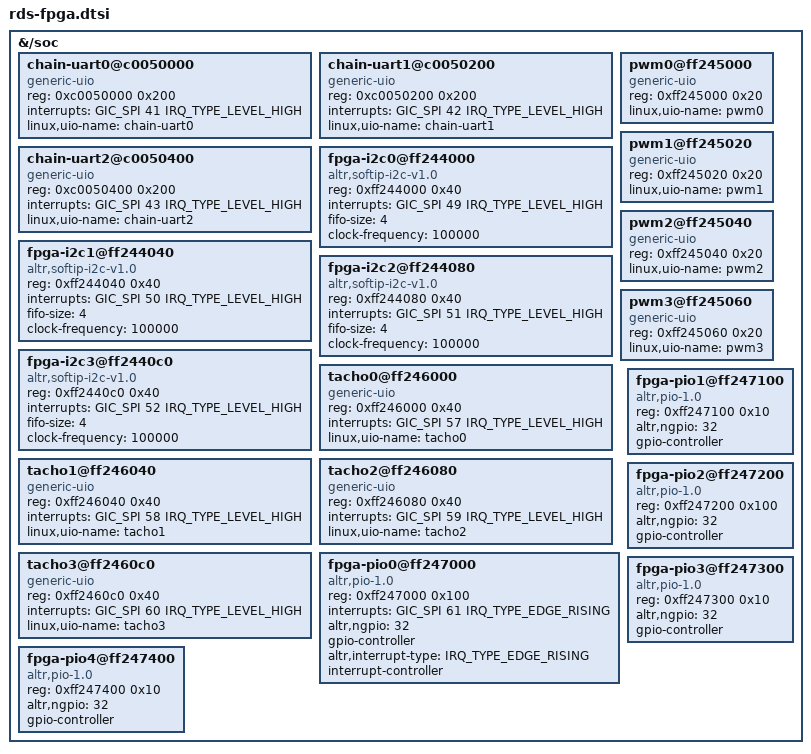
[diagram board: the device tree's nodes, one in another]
// SPDX-License-Identifier: GPL-2.0-or-later
/* GENERATED by tools/hw2dts from os/board/rds-control/hw.toml. Do not edit. */
#include <dt-bindings/interrupt-controller/arm-gic.h>
#include <dt-bindings/interrupt-controller/irq.h>

&{/soc} {
	chain-uart0@c0050000 {
		compatible = "generic-uio";
		reg = <0xc0050000 0x200>;
		interrupts = <GIC_SPI 41 IRQ_TYPE_LEVEL_HIGH>;
		linux,uio-name = "chain-uart0";
	};
	chain-uart1@c0050200 {
		compatible = "generic-uio";
		reg = <0xc0050200 0x200>;
		interrupts = <GIC_SPI 42 IRQ_TYPE_LEVEL_HIGH>;
		linux,uio-name = "chain-uart1";
	};
	chain-uart2@c0050400 {
		compatible = "generic-uio";
		reg = <0xc0050400 0x200>;
		interrupts = <GIC_SPI 43 IRQ_TYPE_LEVEL_HIGH>;
		linux,uio-name = "chain-uart2";
	};
	fpga-i2c0@ff244000 {
		compatible = "altr,softip-i2c-v1.0";
		reg = <0xff244000 0x40>;
		interrupts = <GIC_SPI 49 IRQ_TYPE_LEVEL_HIGH>;
		#address-cells = <1>;
		#size-cells = <0>;
		fifo-size = <4>;
		clock-frequency = <100000>;
	};
	fpga-i2c1@ff244040 {
		compatible = "altr,softip-i2c-v1.0";
		reg = <0xff244040 0x40>;
		interrupts = <GIC_SPI 50 IRQ_TYPE_LEVEL_HIGH>;
		#address-cells = <1>;
		#size-cells = <0>;
		fifo-size = <4>;
		clock-frequency = <100000>;
	};
	fpga-i2c2@ff244080 {
		compatible = "altr,softip-i2c-v1.0";
		reg = <0xff244080 0x40>;
		interrupts = <GIC_SPI 51 IRQ_TYPE_LEVEL_HIGH>;
		#address-cells = <1>;
		#size-cells = <0>;
		fifo-size = <4>;
		clock-frequency = <100000>;
	};
	fpga-i2c3@ff2440c0 {
		compatible = "altr,softip-i2c-v1.0";
		reg = <0xff2440c0 0x40>;
		interrupts = <GIC_SPI 52 IRQ_TYPE_LEVEL_HIGH>;
		#address-cells = <1>;
		#size-cells = <0>;
		fifo-size = <4>;
		clock-frequency = <100000>;
	};
	pwm0@ff245000 {
		compatible = "generic-uio";
		reg = <0xff245000 0x20>;
		linux,uio-name = "pwm0";
	};
	pwm1@ff245020 {
		compatible = "generic-uio";
		reg = <0xff245020 0x20>;
		linux,uio-name = "pwm1";
	};
	pwm2@ff245040 {
		compatible = "generic-uio";
		reg = <0xff245040 0x20>;
		linux,uio-name = "pwm2";
	};
	pwm3@ff245060 {
		compatible = "generic-uio";
		reg = <0xff245060 0x20>;
		linux,uio-name = "pwm3";
	};
	tacho0@ff246000 {
		compatible = "generic-uio";
		reg = <0xff246000 0x40>;
		interrupts = <GIC_SPI 57 IRQ_TYPE_LEVEL_HIGH>;
		linux,uio-name = "tacho0";
	};
	tacho1@ff246040 {
		compatible = "generic-uio";
		reg = <0xff246040 0x40>;
		interrupts = <GIC_SPI 58 IRQ_TYPE_LEVEL_HIGH>;
		linux,uio-name = "tacho1";
	};
	tacho2@ff246080 {
		compatible = "generic-uio";
		reg = <0xff246080 0x40>;
		interrupts = <GIC_SPI 59 IRQ_TYPE_LEVEL_HIGH>;
		linux,uio-name = "tacho2";
	};
	tacho3@ff2460c0 {
		compatible = "generic-uio";
		reg = <0xff2460c0 0x40>;
		interrupts = <GIC_SPI 60 IRQ_TYPE_LEVEL_HIGH>;
		linux,uio-name = "tacho3";
	};
	fpga-pio0@ff247000 {
		compatible = "altr,pio-1.0";
		reg = <0xff247000 0x100>;
		interrupts = <GIC_SPI 61 IRQ_TYPE_EDGE_RISING>;
		altr,ngpio = <32>;
		#gpio-cells = <2>;
		gpio-controller;
		altr,interrupt-type = <IRQ_TYPE_EDGE_RISING>;
		#interrupt-cells = <2>;
		interrupt-controller;
	};
	fpga-pio1@ff247100 {
		compatible = "altr,pio-1.0";
		reg = <0xff247100 0x10>;
		altr,ngpio = <32>;
		#gpio-cells = <2>;
		gpio-controller;
	};
	fpga-pio2@ff247200 {
		compatible = "altr,pio-1.0";
		reg = <0xff247200 0x100>;
		altr,ngpio = <32>;
		#gpio-cells = <2>;
		gpio-controller;
	};
	fpga-pio3@ff247300 {
		compatible = "altr,pio-1.0";
		reg = <0xff247300 0x10>;
		altr,ngpio = <32>;
		#gpio-cells = <2>;
		gpio-controller;
	};
	fpga-pio4@ff247400 {
		compatible = "altr,pio-1.0";
		reg = <0xff247400 0x10>;
		altr,ngpio = <32>;
		#gpio-cells = <2>;
		gpio-controller;
	};
};
